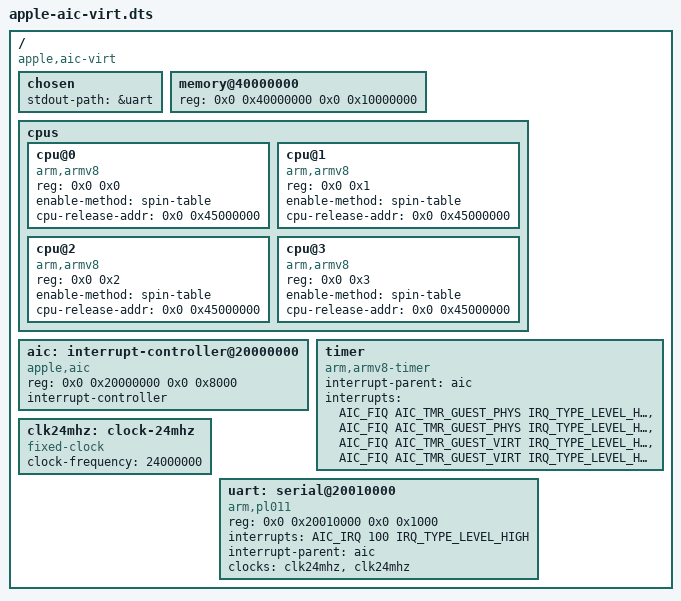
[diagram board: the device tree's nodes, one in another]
/dts-v1/;

#include <dt-bindings/interrupt-controller/apple-aic.h>
#include <dt-bindings/interrupt-controller/irq.h>

/*
 * Spin-table mailbox (0x45000000) and stub (0x45001000). The kernel
 * image occupies 0x40000000-0x443d0000, so this window must be
 * reserved or the kernel will reuse it.
 */
/memreserve/ 0x45000000 0x10000;

/ {
    compatible = "apple,aic-virt";
    #address-cells = <2>;
    #size-cells = <2>;

    chosen {
        stdout-path = &uart;
    };

    memory@40000000 {
        device_type = "memory";
        reg = <0x0 0x40000000 0x0 0x10000000>; /* 256 MiB */
    };

    cpus {
        #address-cells = <2>;
        #size-cells = <0>;

        cpu@0 {
            device_type = "cpu";
            compatible = "arm,armv8";
            reg = <0x0 0x0>;
            enable-method = "spin-table";
            cpu-release-addr = <0x0 0x45000000>;
        };

        cpu@1 {
            device_type = "cpu";
            compatible = "arm,armv8";
            reg = <0x0 0x1>;
            enable-method = "spin-table";
            cpu-release-addr = <0x0 0x45000000>;
        };

        cpu@2 {
            device_type = "cpu";
            compatible = "arm,armv8";
            reg = <0x0 0x2>;
            enable-method = "spin-table";
            cpu-release-addr = <0x0 0x45000000>;
        };

        cpu@3 {
            device_type = "cpu";
            compatible = "arm,armv8";
            reg = <0x0 0x3>;
            enable-method = "spin-table";
            cpu-release-addr = <0x0 0x45000000>;
        };
    };

    aic: interrupt-controller@20000000 {
        compatible = "apple,aic";
        reg = <0x0 0x20000000 0x0 0x8000>;
        interrupt-controller;
        #interrupt-cells = <3>;
    };

    timer {
        compatible = "arm,armv8-timer";
        interrupt-parent = <&aic>;
        /*
         * Order matches the armv8-timer binding: secure phys, non-secure
         * phys, virtual, hypervisor phys. The AIC has no secure/hyp timers
         * here, so the secure and hyp slots reuse the closest source. At
         * EL1 the driver selects the virtual PPI, which the AIC maps to
         * AIC_TMR_EL0_VIRT and delivers as a FIQ.
         */
        interrupts = <AIC_FIQ AIC_TMR_GUEST_PHYS IRQ_TYPE_LEVEL_HIGH>,
                     <AIC_FIQ AIC_TMR_GUEST_PHYS IRQ_TYPE_LEVEL_HIGH>,
                     <AIC_FIQ AIC_TMR_GUEST_VIRT IRQ_TYPE_LEVEL_HIGH>,
                     <AIC_FIQ AIC_TMR_GUEST_VIRT IRQ_TYPE_LEVEL_HIGH>;
    };

    clk24mhz: clock-24mhz {
        compatible = "fixed-clock";
        #clock-cells = <0>;
        clock-frequency = <24000000>;
    };

    uart: serial@20010000 {
        compatible = "arm,pl011", "arm,primecell";
        reg = <0x0 0x20010000 0x0 0x1000>;
        interrupts = <AIC_IRQ 100 IRQ_TYPE_LEVEL_HIGH>;
        interrupt-parent = <&aic>;
        clocks = <&clk24mhz>, <&clk24mhz>;
        clock-names = "uartclk", "apb_pclk";
    };
};
